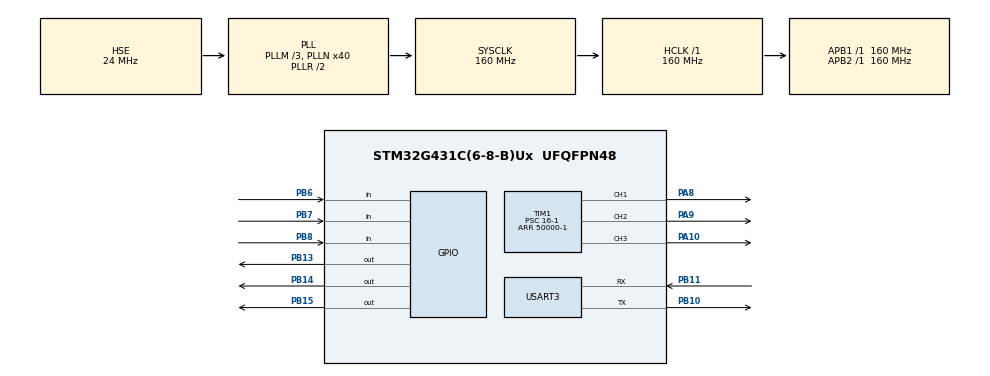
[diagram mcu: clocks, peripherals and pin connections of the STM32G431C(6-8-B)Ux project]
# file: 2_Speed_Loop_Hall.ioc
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Mcu.Family=STM32G4
Mcu.Name=STM32G431C(6-8-B)Ux
Mcu.Package=UFQFPN48
NVIC.PriorityGroup=NVIC_PRIORITYGROUP_4
NVIC.TIM6_DAC_IRQn=true\:0\:0\:false\:false\:true\:true\:true\:true
PA10.Signal=S_TIM1_CH3
PA13.Mode=Serial_Wire
PA13.Signal=SYS_JTMS-SWDIO
PA14.Mode=Serial_Wire
PA14.Signal=SYS_JTCK-SWCLK
PA8.Signal=S_TIM1_CH1
PA9.Signal=S_TIM1_CH2
PB10.Mode=Asynchronous
PB10.Signal=USART3_TX
PB11.Mode=Asynchronous
PB11.Signal=USART3_RX
PB13.Signal=GPIO_Output
PB14.Signal=GPIO_Output
PB15.Signal=GPIO_Output
PB6.GPIO_PuPd=GPIO_PULLDOWN
PB6.Signal=GPIO_Input
PB7.GPIO_PuPd=GPIO_PULLDOWN
PB7.Signal=GPIO_Input
PB8-BOOT0.GPIO_PuPd=GPIO_PULLDOWN
PB8-BOOT0.Signal=GPIO_Input
PF0-OSC_IN.Mode=HSE-External-Oscillator
PF0-OSC_IN.Signal=RCC_OSC_IN
PF1-OSC_OUT.Mode=HSE-External-Oscillator
PF1-OSC_OUT.Signal=RCC_OSC_OUT
ProjectManager.HeapSize=0x200
ProjectManager.StackSize=0x400
ProjectManager.TargetToolchain=Makefile
RCC.ADC12Freq_Value=160000000
RCC.AHBFreq_Value=160000000
RCC.APB1Freq_Value=160000000
RCC.APB1TimFreq_Value=160000000
RCC.APB2Freq_Value=160000000
RCC.APB2TimFreq_Value=160000000
RCC.CortexFreq_Value=160000000
RCC.EXTERNAL_CLOCK_VALUE=12288000
RCC.HCLKFreq_Value=160000000
RCC.HSE_VALUE=24000000
RCC.HSI48_VALUE=48000000
RCC.HSI_VALUE=16000000
RCC.LSE_VALUE=32768
RCC.PLLM=RCC_PLLM_DIV3
RCC.PLLN=40
RCC.PLLSourceVirtual=RCC_PLLSOURCE_HSE
RCC.SYSCLKFreq_VALUE=160000000
RCC.SYSCLKSource=RCC_SYSCLKSOURCE_PLLCLK
RCC.USBFreq_Value=160000000
RCC.VCOOutputFreq_Value=320000000
SH.S_TIM1_CH1.0=TIM1_CH1,PWM Generation1 CH1
SH.S_TIM1_CH2.0=TIM1_CH2,PWM Generation2 CH2
SH.S_TIM1_CH3.0=TIM1_CH3,PWM Generation3 CH3
TIM1.Channel-PWM\ Generation1\ CH1=TIM_CHANNEL_1
TIM1.Channel-PWM\ Generation2\ CH2=TIM_CHANNEL_2
TIM1.Channel-PWM\ Generation3\ CH3=TIM_CHANNEL_3
TIM1.PeriodNoDither=50000-1
TIM1.Prescaler=16-1
TIM6.PeriodNoDither=50-1
TIM6.Prescaler=160-1
USART3.VirtualMode-Asynchronous=VM_ASYNC
VP_SYS_VS_DBSignals.Mode=DisableDeadBatterySignals
VP_TIM6_VS_ClockSourceINT.Mode=Enable_Timer
board=custom

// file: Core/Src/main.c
/* USER CODE BEGIN Header */
/**
 ******************************************************************************
 * @file           : main.c
 * @brief          : Main program body
 ******************************************************************************
 * @attention
 *
 * Copyright (c) 2023 STMicroelectronics.
 * All rights reserved.
 *
 * This software is licensed under terms that can be found in the LICENSE file
 * in the root directory of this software component.
 * If no LICENSE file comes with this software, it is provided AS-IS.
 *
 ******************************************************************************
 */
/* USER CODE END Header */
#include "main.h"
#include "tim.h"
#include "usart.h"
#include "gpio.h"

/* USER CODE BEGIN Includes */
#include <stdio.h>
#include "bldc.h"
/* USER CODE END Includes */

void SystemClock_Config(void);

/* USER CODE BEGIN 0 */
extern PID speed_pid;
extern BLDC_Motor motor;
/* USER CODE END 0 */

int main(void)
{

    /* MCU Configuration--------------------------------------------------------*/

    /* Reset of all peripherals, Initializes the Flash interface and the Systick. */
    HAL_Init();

    /* Configure the system clock */
    SystemClock_Config();

    /* Initialize all configured peripherals */
    MX_GPIO_Init();
    MX_TIM1_Init();
    MX_TIM6_Init();
    MX_USART3_UART_Init();
    /* USER CODE BEGIN 2 */
    BLDC_Motor_Init();
    BLDC_Motor_Speed_Set(500);

    /* USER CODE END 2 */

    /* Infinite loop */
    while (1) {

        /* USER CODE BEGIN 3 */

        motor.run_flag = RUN;
        BLDC_Motor_Start();
        printf("%ld,%d\r\n", motor.speed, motor.pwm_duty);
    }
    /* USER CODE END 3 */
}

void SystemClock_Config(void)
{
    RCC_OscInitTypeDef RCC_OscInitStruct = {0};
    RCC_ClkInitTypeDef RCC_ClkInitStruct = {0};

    /** Configure the main internal regulator output voltage
     */
    HAL_PWREx_ControlVoltageScaling(PWR_REGULATOR_VOLTAGE_SCALE1_BOOST);

    /** Initializes the RCC Oscillators according to the specified parameters
     * in the RCC_OscInitTypeDef structure.
     */
    RCC_OscInitStruct.OscillatorType = RCC_OSCILLATORTYPE_HSE;
    RCC_OscInitStruct.HSEState       = RCC_HSE_ON;
    RCC_OscInitStruct.PLL.PLLState   = RCC_PLL_ON;
    RCC_OscInitStruct.PLL.PLLSource  = RCC_PLLSOURCE_HSE;
    RCC_OscInitStruct.PLL.PLLM       = RCC_PLLM_DIV3;
    RCC_OscInitStruct.PLL.PLLN       = 40;
    RCC_OscInitStruct.PLL.PLLP       = RCC_PLLP_DIV2;
    RCC_OscInitStruct.PLL.PLLQ       = RCC_PLLQ_DIV2;
    RCC_OscInitStruct.PLL.PLLR       = RCC_PLLR_DIV2;
    if (HAL_RCC_OscConfig(&RCC_OscInitStruct) != HAL_OK) {
        Error_Handler();
    }

    /** Initializes the CPU, AHB and APB buses clocks
     */
    RCC_ClkInitStruct.ClockType      = RCC_CLOCKTYPE_HCLK | RCC_CLOCKTYPE_SYSCLK | RCC_CLOCKTYPE_PCLK1 | RCC_CLOCKTYPE_PCLK2;
    RCC_ClkInitStruct.SYSCLKSource   = RCC_SYSCLKSOURCE_PLLCLK;
    RCC_ClkInitStruct.AHBCLKDivider  = RCC_SYSCLK_DIV1;
    RCC_ClkInitStruct.APB1CLKDivider = RCC_HCLK_DIV1;
    RCC_ClkInitStruct.APB2CLKDivider = RCC_HCLK_DIV1;

    if (HAL_RCC_ClockConfig(&RCC_ClkInitStruct, FLASH_LATENCY_4) != HAL_OK) {
        Error_Handler();
    }
}

void Error_Handler(void)
{
    __disable_irq();
    while (1) {
    }
}
